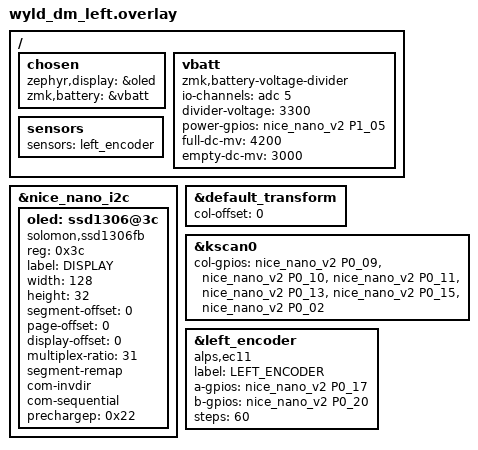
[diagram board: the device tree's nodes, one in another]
#include "wyld_dm_common.dtsi"

/ {
    chosen {
        zephyr,display = &oled;
        zmk,battery = &vbatt;
    };

    vbatt: vbatt {
        compatible = "zmk,battery-voltage-divider";
        io-channels = <&adc 5>;
        divider-voltage = <3300>;
        // Correct pin reference for nice_nano_v2
        power-gpios = <&nice_nano_v2 P1_05 GPIO_ACTIVE_HIGH>;
        full-dc-mv = <4200>;
        empty-dc-mv = <3000>;
    };

    sensors {
        sensors = <&left_encoder>;
    };
};

// Correct I2C bus reference for nice_nano_v2
&nice_nano_i2c {
    status = "okay";
    oled: ssd1306@3c {
        compatible = "solomon,ssd1306fb";
        reg = <0x3c>;
        label = "DISPLAY";
        width = <128>;
        height = <32>;
        segment-offset = <0>;
        page-offset = <0>;
        display-offset = <0>;
        multiplex-ratio = <31>;
        segment-remap;
        com-invdir;
        com-sequential;
        prechargep = <0x22>;
    };
};

&default_transform {
    col-offset = <0>;
};

&kscan0 {
    col-gpios
        = <&nice_nano_v2 P0_09 GPIO_ACTIVE_HIGH>
        , <&nice_nano_v2 P0_10 GPIO_ACTIVE_HIGH>
        , <&nice_nano_v2 P0_11 GPIO_ACTIVE_HIGH>
        , <&nice_nano_v2 P0_13 GPIO_ACTIVE_HIGH>
        , <&nice_nano_v2 P0_15 GPIO_ACTIVE_HIGH>
        , <&nice_nano_v2 P0_02 GPIO_ACTIVE_HIGH>
        ;
};

// Corrected encoder pins for nice_nano_v2 (example pins)
&left_encoder {
    compatible = "alps,ec11";
    label = "LEFT_ENCODER";
    a-gpios = <&nice_nano_v2 P0_17 (GPIO_ACTIVE_HIGH | GPIO_PULL_UP)>;
    b-gpios = <&nice_nano_v2 P0_20 (GPIO_ACTIVE_HIGH | GPIO_PULL_UP)>;
    steps = <60>;
    status = "okay";
};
